VERSION "10-05-2017 11:45:40"

BS_:

BU_: CAEMAX

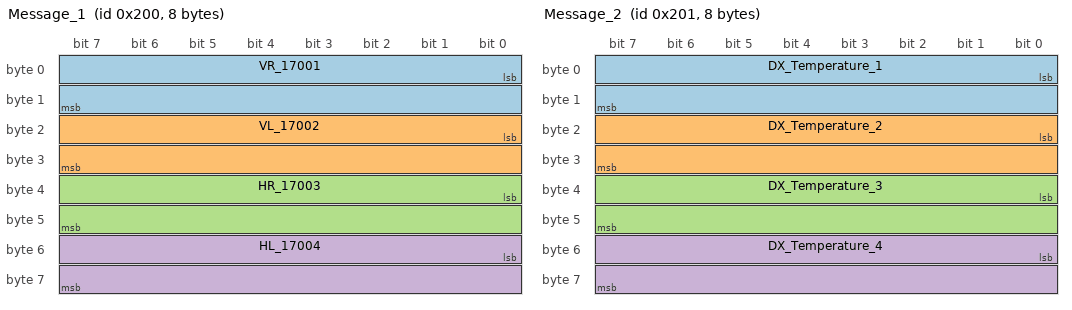
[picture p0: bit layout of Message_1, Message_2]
BO_ 512 Message_1: 8 CAEMAX
 SG_ VR_17001 :  0|16@1+ (0.00012090,-3.96170000) [-3.961700|3.961700] "kNm     " CAEMAX
 SG_ VL_17002 : 16|16@1+ (0.00012081,-3.95871000) [-3.958710|3.958710] "kNm     " CAEMAX
 SG_ HR_17003 : 32|16@1+ (0.00011994,-3.93006000) [-3.930060|3.930060] "kNm     " CAEMAX
 SG_ HL_17004 : 48|16@1+ (0.00011980,-3.92572000) [-3.925720|3.925720] "kNm     " CAEMAX

BO_ 513 Message_2: 8 CAEMAX
 SG_ DX_Temperature_1 :  0|16@1+ (0.03451538,-1131.00000000) [-1131.000000|1131.000000] "°C      " CAEMAX
 SG_ DX_Temperature_2 : 16|16@1+ (0.03451538,-1131.00000000) [-1131.000000|1131.000000] "°C      " CAEMAX
 SG_ DX_Temperature_3 : 32|16@1+ (0.03451538,-1131.00000000) [-1131.000000|1131.000000] "°C      " CAEMAX
 SG_ DX_Temperature_4 : 48|16@1+ (0.03451538,-1131.00000000) [-1131.000000|1131.000000] "°C      " CAEMAX

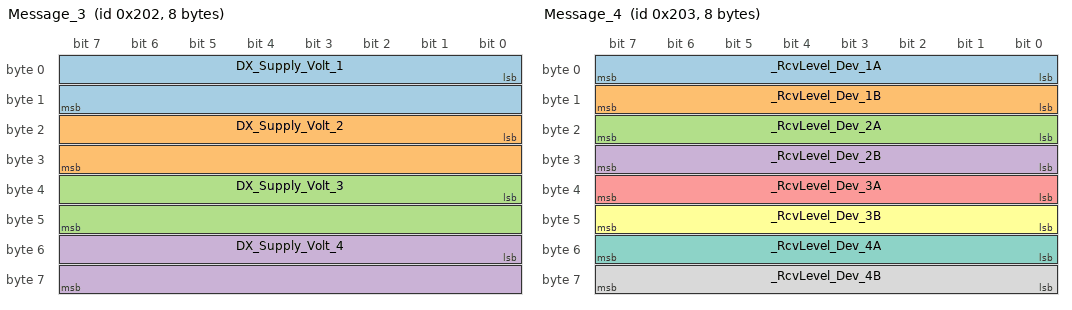
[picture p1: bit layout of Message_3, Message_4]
BO_ 514 Message_3: 8 CAEMAX
 SG_ DX_Supply_Volt_1 :  0|16@1+ (0.00126648,-41.50000000) [-41.500000|41.500000] "V       " CAEMAX
 SG_ DX_Supply_Volt_2 : 16|16@1+ (0.00126648,-41.50000000) [-41.500000|41.500000] "V       " CAEMAX
 SG_ DX_Supply_Volt_3 : 32|16@1+ (0.00126648,-41.50000000) [-41.500000|41.500000] "V       " CAEMAX
 SG_ DX_Supply_Volt_4 : 48|16@1+ (0.00126648,-41.50000000) [-41.500000|41.500000] "V       " CAEMAX

BO_ 515 Message_4: 8 CAEMAX
 SG_ _RcvLevel_Dev_1A :  0|8@1- (1.0,0.0) [-128|127] "dBm" CAEMAX
 SG_ _RcvLevel_Dev_1B :  8|8@1- (1.0,0.0) [-128|127] "dBm" CAEMAX
 SG_ _RcvLevel_Dev_2A : 16|8@1- (1.0,0.0) [-128|127] "dBm" CAEMAX
 SG_ _RcvLevel_Dev_2B : 24|8@1- (1.0,0.0) [-128|127] "dBm" CAEMAX
 SG_ _RcvLevel_Dev_3A : 32|8@1- (1.0,0.0) [-128|127] "dBm" CAEMAX
 SG_ _RcvLevel_Dev_3B : 40|8@1- (1.0,0.0) [-128|127] "dBm" CAEMAX
 SG_ _RcvLevel_Dev_4A : 48|8@1- (1.0,0.0) [-128|127] "dBm" CAEMAX
 SG_ _RcvLevel_Dev_4B : 56|8@1- (1.0,0.0) [-128|127] "dBm" CAEMAX
